# STM32G544xx register map
File version: 1.0
Registers are 32-bit, read-write, reset 0x0 unless marked. A register's access mark holds for its fields unless they carry their own. Offsets are from the block's base; [hi:lo] are bit positions; {n}, {i} and the like mark numbered series.

## GPIOA — General-purpose I/Os (GPIO)
Base 0x46000000
Same registers: GPIOB 0x46000400, GPIOC 0x46000800, GPIOD 0x46000C00, GPIOE 0x46001000, GPIOF 0x46001400, GPIOG 0x46001800, GPIOH 0x46001C00
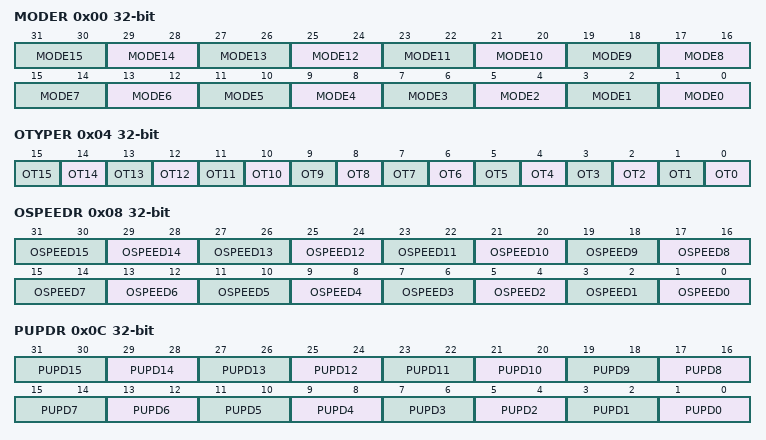
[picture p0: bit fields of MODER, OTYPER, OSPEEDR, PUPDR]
0x00 MODER — GPIO port mode register
  [2n+1:2n] MODE{n} (n=0..15) — Port x configuration I/O pin y
0x04 OTYPER — GPIO port output type register
  [n] OT{n} (n=0..15) — Port x configuration I/O pin y
0x08 OSPEEDR — GPIO port output speed register
  [2n+1:2n] OSPEED{n} (n=0..15) — Port x configuration I/O pin y
0x0C PUPDR — GPIO port pull-up/pull-down register
  [2n+1:2n] PUPD{n} (n=0..15) — Port x configuration I/O pin y
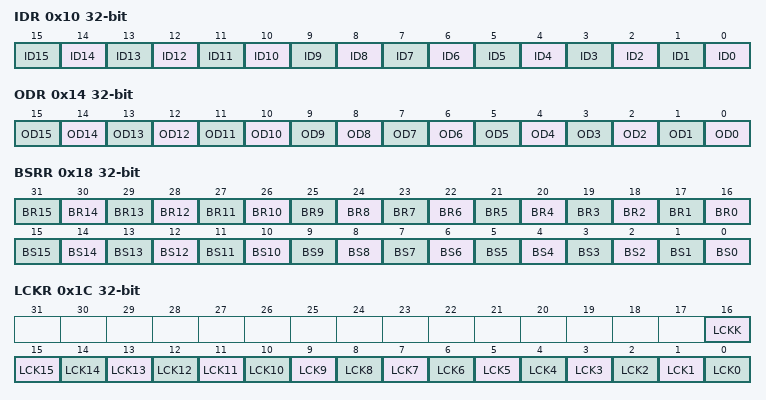
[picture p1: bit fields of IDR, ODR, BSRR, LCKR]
0x10 IDR ro — GPIO port input data register
  [n] ID{n} (n=0..15) — Port x input data I/O pin y
0x14 ODR — GPIO port output data register
  [n] OD{n} (n=0..15) — Port output data I/O pin y
0x18 BSRR — GPIO port bit set/reset register
  [n+16] BR{n} (n=0..15) — Port x reset I/O pin y
  [n] BS{n} (n=0..15) — Port x set I/O pin y
0x1C LCKR — GPIO port configuration lock register
  [16] LCKK — Lock key
  [n] LCK{n} (n=0..15) — Port x lock I/O pin y
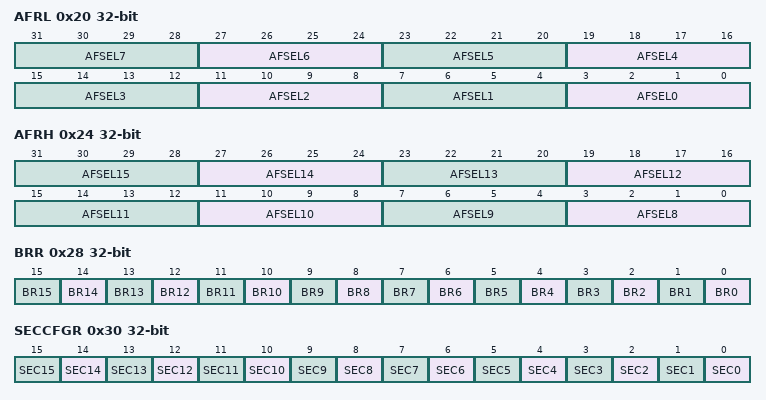
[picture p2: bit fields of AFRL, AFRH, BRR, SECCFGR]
0x20 AFRL — GPIO alternate function low register
  [4n+3:4n] AFSEL{n} (n=0..7)
0x24 AFRH — GPIO alternate function low register
  [4n-29:4n-32] AFSEL{n} (n=8..15)
0x28 BRR — GPIO port bit reset register
  [n] BR{n} (n=0..15) — Port x reset IO pin y
0x30 SECCFGR — GPIO secure configuration register
  [n] SEC{n} (n=0..15) — I/O pin of Port x secure bit enable y

## AES — AES hardware accelerator (AES)
Base 0x46006000
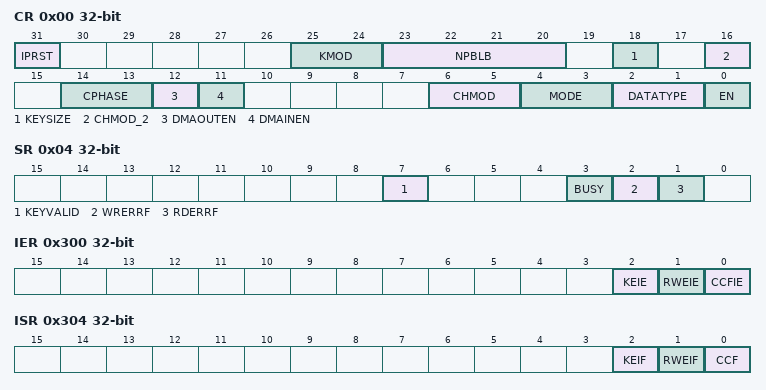
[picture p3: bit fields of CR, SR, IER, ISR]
0x00 CR — AES control register
  [31] IPRST — AES peripheral software reset
  [25:24] KMOD — Key mode selection
  [23:20] NPBLB — Number of padding bytes in last block
  [18] KEYSIZE — Key size selection
  [16] CHMOD_2 — CHMOD[1:0]: Chaining mode, CHMOD[2]
  [14:13] CPHASE — Chaining phase selection
  [12] DMAOUTEN — DMA output enable
  [11] DMAINEN — DMA input enable
  [6:5] CHMOD — CHMOD[1:0]: Chaining mode, CHMOD[2]
  [4:3] MODE — Operating mode
  [2:1] DATATYPE
  [0] EN — Enable
0x04 SR ro — AES status register
  [7] KEYVALID — Key valid flag
  [3] BUSY
  [2] WRERRF — Write error flag
  [1] RDERRF — Read error flag
0x08 DINR — AES data input register
  [31:0] DIN — Data input
0x0C DOUTR ro — AES data output register
  [31:0] DOUT — Data output
{0x10+4i} KEYR{i} (i=0..3) — AES key register {i}
  [31:0] KEY — Cryptographic key, bits [{32i+31}:{32i}]
{0x20+4i} IVR{i} (i=0..3) — AES initialization vector register {i}
  [31:0] IVI — Initialization vector input, bits [{32i+31}:{32i}]
{0x20+4i} KEYR{i} (i=4..7) — AES key register {i}
  [31:0] KEY — Cryptographic key, bits [{32i+31}:{32i}]
{0x40+4i} SUSPR{i} (i=0..7) — AES suspend registers
  [31:0] SUSP — Suspend data
0x300 IER — AES interrupt enable register
  [2] KEIE — Key error interrupt enable
  [1] RWEIE — Read or write error interrupt enable
  [0] CCFIE — Computation complete flag interrupt enable
0x304 ISR ro — AES interrupt status register
  [2] KEIF — Key error interrupt flag
  [1] RWEIF — Read or write error interrupt flag
  [0] CCF — Computation complete flag
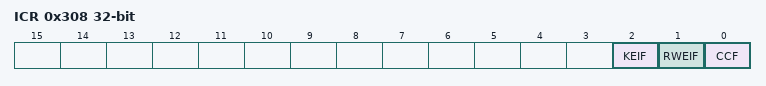
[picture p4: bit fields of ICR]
0x308 ICR — AES interrupt clear register
  [2] KEIF — Key error interrupt flag clear
  [1] RWEIF — Read or write error interrupt flag clear
  [0] CCF — Computation complete flag clear

## HASH — Hash processor (HASH)
Base 0x46006400
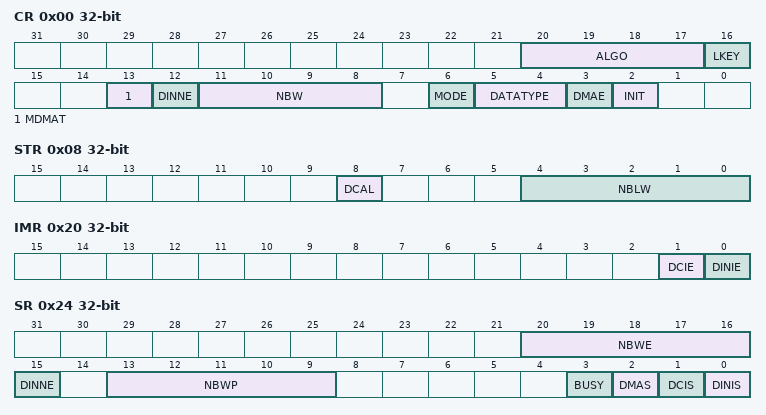
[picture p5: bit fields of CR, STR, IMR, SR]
0x00 CR — HASH control register
  [20:17] ALGO — Algorithm selection
  [16] LKEY — Long key selection
  [13] MDMAT — Multiple DMA transfers
  [12] DINNE — DIN not empty
  [11:8] NBW
  [6] MODE — Mode selection
  [5:4] DATATYPE — Data type selection
  [3] DMAE — DMA enable
  [2] INIT
0x04 DIN — HASH data input register
  [31:0] DATAIN — Data input
0x08 STR — HASH start register
  [8] DCAL — Digest calculation
  [4:0] NBLW
{0xC+4i} HRA{i} ro (i=0..4) — HASH aliased digest register
  [31:0] H — Hash data x
0x20 IMR — HASH interrupt enable register
  [1] DCIE
  [0] DINIE — Data input interrupt enable
0x24 SR — HASH status register
  [20:16] NBWE — Number of words expected
  [15] DINNE — DIN not empty
  [13:9] NBWP
  [3] BUSY — Busy bit
  [2] DMAS — DMA Status
  [1] DCIS
  [0] DINIS — Data input interrupt status
{0xF8+4i} CSR{i} (i=0..102) — HASH context swap register
  [31:0] CS — Context swap x
{0x310+4i} HR{i} ro (i=0..15) — HASH digest register
  [31:0] H — Hash data x

## RNG — True random number generator (RNG)
Base 0x46006800
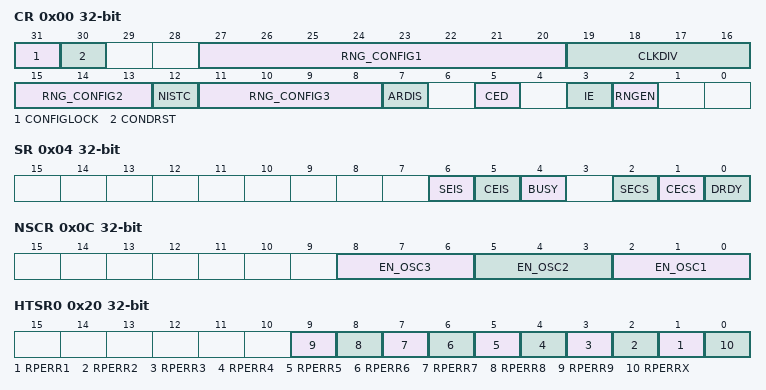
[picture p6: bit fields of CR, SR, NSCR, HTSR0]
0x00 CR — RNG control register
  [31] CONFIGLOCK — RNG configuration lock
  [30] CONDRST — Conditioning soft reset
  [27:20] RNG_CONFIG1 — RNG configuration 1
  [19:16] CLKDIV — Clock divider factor
  [15:13] RNG_CONFIG2 — RNG configuration 2
  [12] NISTC — NIST custom
  [11:8] RNG_CONFIG3 — RNG configuration 3
  [7] ARDIS — Auto reset disable
  [5] CED — Clock error detection
  [3] IE — Interrupt enable
  [2] RNGEN — True random number generator enable
0x04 SR — RNG status register
  [6] SEIS — Seed error interrupt status
  [5] CEIS — Clock error interrupt status
  [4] BUSY
  [2] SECS — Seed error current status
  [1] CECS — Clock error current status
  [0] DRDY — Data ready
0x08 DR ro — RNG data register
  [31:0] RNDATA — Random data
0x0C NSCR — RNG noise source control register
  [8:6] EN_OSC3, [5:3] EN_OSC2, [2:0] EN_OSC1
{0x10+4i} HTCR{i} (i=0..3) — RNG health test control register
  [31:0] HTCFG — health test configuration
0x20 HTSR0 ro — RNG health test status register
  [n] RPERR{n} (n=1..9) — Repetitive error for oscillator i
  [0] RPERRX — Repetitive error after the XOR
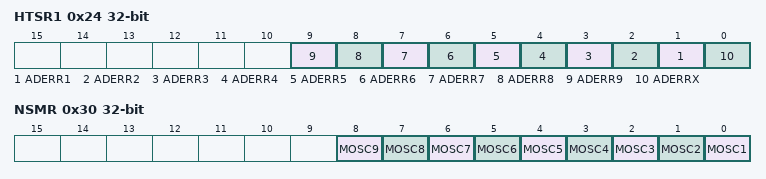
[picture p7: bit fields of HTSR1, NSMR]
0x24 HTSR1 ro — RNG health test status register
  [n] ADERR{n} (n=1..9) — Adaptative error for oscillator i
  [0] ADERRX — Adaptative error after the XOR
0x30 NSMR — RNG noise source mask register
  [n-1] MOSC{n} (n=1..9) — Mask oscillator i

## PKA — Public key accelerator (PKA)
Base 0x46008000
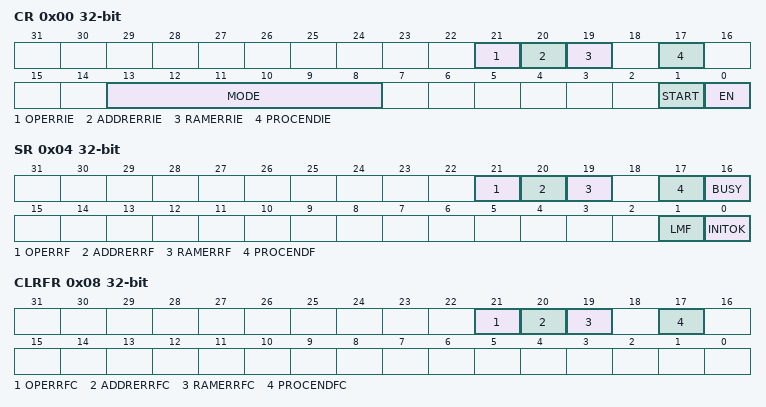
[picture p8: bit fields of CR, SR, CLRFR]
0x00 CR — PKA control register
  [21] OPERRIE — Operation error interrupt enable
  [20] ADDRERRIE — Address error interrupt enable
  [19] RAMERRIE — RAM error interrupt enable
  [17] PROCENDIE — End of operation interrupt enable
  [13:8] MODE — PKA operation code
  [1] START — start the operation
  [0] EN — PKA enable
0x04 SR ro — PKA status register
  [21] OPERRF — Operation error flag
  [20] ADDRERRF — Address error flag
  [19] RAMERRF — PKA RAM error flag
  [17] PROCENDF — PKA end of operation flag
  [16] BUSY — Busy flag
  [1] LMF — Limited mode flag
  [0] INITOK — PKA initialization OK
0x08 CLRFR — PKA clear flag register
  [21] OPERRFC — Clear operation error flag
  [20] ADDRERRFC — Clear address error flag
  [19] RAMERRFC — Clear PKA RAM error flag
  [17] PROCENDFC — Clear PKA end of operation flag
{0x400+4i} RAM[{i}] (i=0..1333)
